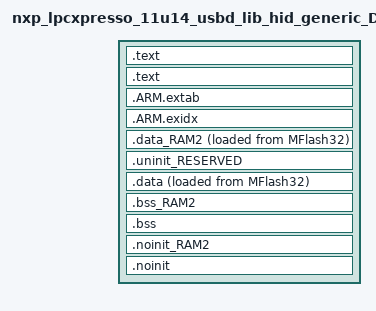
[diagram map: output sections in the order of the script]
/*
 * GENERATED FILE - DO NOT EDIT
 * (c) Code Red Technologies Ltd, 2008-13
 * (c) NXP Semiconductors 2013-2017
 * Generated linker script file for LPC11U24/301
 * Created from generic_c.ld (7.7.2 ())
 * By LPCXpresso v7.7.2 [Build 379] [2015-03-31]  on Thu Jan 05 18:28:50 AEDT 2017
 */


INCLUDE "nxp_lpcxpresso_11u14_usbd_lib_hid_generic_Debug_lib.ld"
INCLUDE "nxp_lpcxpresso_11u14_usbd_lib_hid_generic_Debug_mem.ld"

ENTRY(ResetISR)

SECTIONS
{

    /* MAIN TEXT SECTION */    
    .text : ALIGN(4)
    {
        FILL(0xff)
        __vectors_start__ = ABSOLUTE(.) ;
        KEEP(*(.isr_vector))
        
        /* Global Section Table */
        . = ALIGN(4) ;
        __section_table_start = .;
        __data_section_table = .;
        LONG(LOADADDR(.data));
        LONG(    ADDR(.data));
        LONG(  SIZEOF(.data));
        LONG(LOADADDR(.data_RAM2));
        LONG(    ADDR(.data_RAM2));
        LONG(  SIZEOF(.data_RAM2));
        __data_section_table_end = .;
        __bss_section_table = .;
        LONG(    ADDR(.bss));
        LONG(  SIZEOF(.bss));
        LONG(    ADDR(.bss_RAM2));
        LONG(  SIZEOF(.bss_RAM2));
        __bss_section_table_end = .;
        __section_table_end = . ;
        /* End of Global Section Table */
        

        *(.after_vectors*)
        
    } >MFlash32
    
    .text : ALIGN(4)    
    {
         *(.text*)
        *(.rodata .rodata.* .constdata .constdata.*)
        . = ALIGN(4);
        
    } > MFlash32

    /*
     * for exception handling/unwind - some Newlib functions (in common
     * with C++ and STDC++) use this. 
     */
    .ARM.extab : ALIGN(4)
    {
    	*(.ARM.extab* .gnu.linkonce.armextab.*)
    } > MFlash32
    __exidx_start = .;
    
    .ARM.exidx : ALIGN(4)
    {
    	*(.ARM.exidx* .gnu.linkonce.armexidx.*)
    } > MFlash32
    __exidx_end = .;
    
    _etext = .;
        
    
    /* DATA section for RamUsb2 */
    .data_RAM2 : ALIGN(4)
    {
       FILL(0xff)
       PROVIDE(__start_data_RAM2 = .) ;
       *(.ramfunc.$RAM2)
       *(.ramfunc.$RamUsb2)
    	*(.data.$RAM2*)
    	*(.data.$RamUsb2*)
       . = ALIGN(4) ;
       PROVIDE(__end_data_RAM2 = .) ;
    } > RamUsb2 AT>MFlash32
    
    /* MAIN DATA SECTION */
    

    .uninit_RESERVED : ALIGN(4)
    {
        KEEP(*(.bss.$RESERVED*))
        . = ALIGN(4) ;
        _end_uninit_RESERVED = .;
    } > RamLoc6

	
	/* Main DATA section (RamLoc6) */
	.data : ALIGN(4)
	{
	   FILL(0xff)
	   _data = . ;
	   *(vtable)
	   *(.ramfunc*)
	   *(.data*)
	   . = ALIGN(4) ;
	   _edata = . ;
	} > RamLoc6 AT>MFlash32

    /* BSS section for RamUsb2 */
    .bss_RAM2 : ALIGN(4)
    {
       PROVIDE(__start_bss_RAM2 = .) ;
    	*(.bss.$RAM2*)
    	*(.bss.$RamUsb2*)
       . = ALIGN(4) ;
       PROVIDE(__end_bss_RAM2 = .) ;
    } > RamUsb2

    /* MAIN BSS SECTION */
    .bss : ALIGN(4)
    {
        _bss = .;
        *(.bss*)
        *(COMMON)
        . = ALIGN(4) ;
        _ebss = .;
        PROVIDE(end = .);
    } > RamLoc6
        
    /* NOINIT section for RamUsb2 */
    .noinit_RAM2 (NOLOAD) : ALIGN(4)
    {
    	*(.noinit.$RAM2*)
    	*(.noinit.$RamUsb2*)
       . = ALIGN(4) ;
    } > RamUsb2 
    
    /* DEFAULT NOINIT SECTION */
    .noinit (NOLOAD): ALIGN(4)
    {
        _noinit = .;
        *(.noinit*) 
         . = ALIGN(4) ;
        _end_noinit = .;
    } > RamLoc6
    
    PROVIDE(_pvHeapStart = DEFINED(__user_heap_base) ? __user_heap_base : .);
    PROVIDE(_vStackTop = DEFINED(__user_stack_top) ? __user_stack_top : __top_RamLoc6 - 0);
}
